# EDMA_TPTC_52A60000h register map
Vendor: Texas Instruments
Peripheral module from a debugger description file (folder AM261x).
Registers are 32-bit, read-only, reset 0x0 unless marked. A register's access mark holds for its fields unless they carry their own. Offsets are as the file gives them; lines under a group give offsets from that group; [hi:lo] are bit positions; {n}, {i} and the like mark numbered series; 'fields as' and 'values as' point back to an identical list; <NAME> marks a mode.

## TPTC
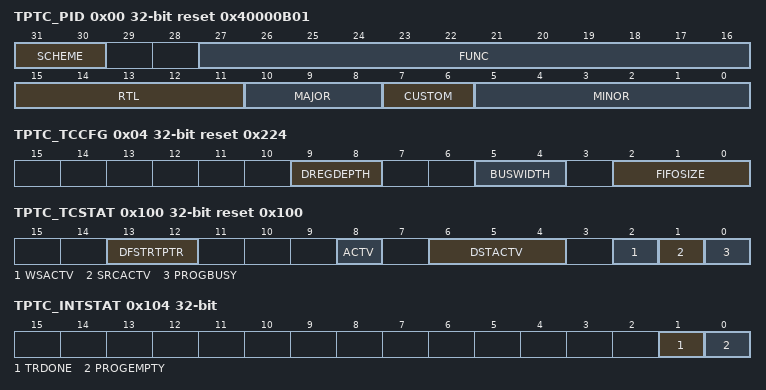
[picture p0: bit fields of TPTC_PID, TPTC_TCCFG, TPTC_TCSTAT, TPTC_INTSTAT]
0x00 TPTC_PID reset 0x40000B01 — Peripheral ID Register.
  [31:30] SCHEME — PID Scheme: Used to distinguish between old ID scheme and current. Spare bit to encode future schemes EDMA uses 'new scheme' indicated with value of 0x1.
  [27:16] FUNC — Function indicates a software compatible module family.
  [15:11] RTL — RTL Version
  [10:8] MAJOR — Major Revision
  [7:6] CUSTOM — Custom revision field: Not used on this version of EDMA.
  [5:0] MINOR — Minor Revision
0x04 TPTC_TCCFG reset 0x224 — TC Configuration Register.
  [9:8] DREGDEPTH — Dst Register FIFO Depth Parameterization
  [5:4] BUSWIDTH — Bus Width Parameterization
  [2:0] FIFOSIZE — Fifo Size Parameterization
0x100 TPTC_TCSTAT reset 0x100 — TC Status Register.
  [13:12] DFSTRTPTR — Dst FIFO Start PointerRepresents the offset to the head entry of Dst Register FIFO in units of entries. Legal values = 0x0 to 0x3
  [8] ACTV — Channel ActiveChannel Active is a logical-OR of each of the BUSY/ACTV signals. The ACTV bit must remain high through the life of a TR.ACTV =0 : Channel is idle.ACTV =1 : Channel is busy.
  [6:4] DSTACTV — Destination Active StateSpecifies the number of TRs that are resident in the Dst Register FIFO at a given instant.Legal values are constrained by the DSTREGDEPTH parameter.
  [2] WSACTV — Write Status ActiveWSACTV =0 : Write status is not pending. Write status has been received for all previously issued write commands.WSACTV =1 : Write Status is pending. Write status has not been received for all previously issued write commands.
  [1] SRCACTV — Source Active StateSRCACTV =0 : Source Active set is idle. Any TR written to Prog Set will immediately transition to Source Active set as long as the Dst FIFO Set is not full [DSTFULL == 1].SRCACTV =1 : Source Active set is busy either performing read transfers or waiting to perform read transfers for current Transfer Request.
  [0] PROGBUSY — Program Register Set BusyPROGBUSY =0 : Prog set idle and is available for programming.PROGBUSY =1 : Prog set busy. User should poll for PROGBUSY equal to '0' prior to re-programming the Program Register set.
0x104 TPTC_INTSTAT — Interrupt Status Register.
  [1] TRDONE — TR Done Event Status:TRDONE =0 : Condition not detected.TRDONE =1 : Set when TC has completed a Transfer Request. TRDONE should be set when the write status is returned for the final write of a TR. Cleared when user writes '1' to INTCLR.TRDONE register bit.
  [0] PROGEMPTY — Program Set Empty Event Status:PROGEMPTY =0 : Condition not detected.PROGEMPTY =1 : Set when Program Register set transitions to empty state. Cleared when user writes '1' to INTCLR.PROGEMPTY register bit.
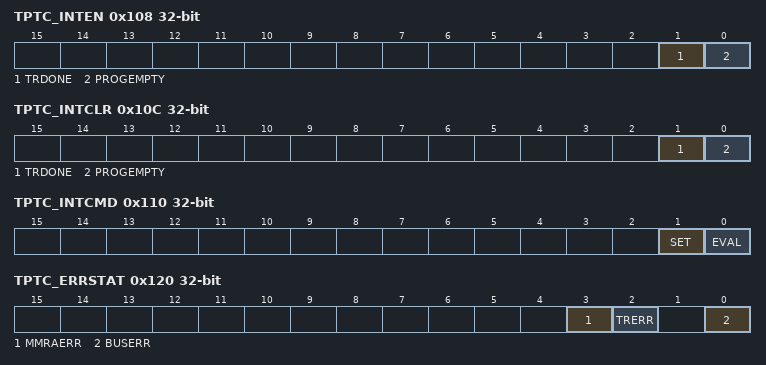
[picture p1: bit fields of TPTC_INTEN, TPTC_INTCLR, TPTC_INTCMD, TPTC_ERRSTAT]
0x108 TPTC_INTEN rw — Interrupt Enable Register.
  [1] TRDONE — TR Done Event Enable:INTEN.TRDONE =0 : TRDONE Event is disabled.INTEN.TRDONE =1 : TRDONE Event is enabled and contributes to interrupt generation
  [0] PROGEMPTY — Program Set Empty Event Enable:INTEN.PROGEMPTY =0 : PROGEMPTY Event is disabled.INTEN.PROGEMPTY =1 : PROGEMPTY Event is enabled and contributes to interrupt generation
0x10C TPTC_INTCLR wo — Interrupt Clear Register.
  [1] TRDONE — TR Done Event Clear:INTCLR.TRDONE =0 : Writes of '0' have no effect.INTCLR.TRDONE =1 : Write of '1' clears INTSTAT.TRDONE bit
  [0] PROGEMPTY — Program Set Empty Event Clear:INTCLR.PROGEMPTY =0 : Writes of '0' have no effect.INTCLR.PROGEMPTY =1 : Write of '1' clears INTSTAT.PROGEMPTY bit
0x110 TPTC_INTCMD wo — Interrupt Command Register.
  [1] SET — Set TPTC interrupt:Write of '1' to SET causes TPTC interrupt to be pulsed unconditionally.Writes of '0' have no affect.
  [0] EVAL — Evaluate state of TPTC interruptWrite of '1' to EVAL causes TPTC interrupt to be pulsed if any of the INTSTAT bits are set to '1'.Writes of '0' have no affect.
0x120 TPTC_ERRSTAT — Error Status Register.
  [3] MMRAERR — MMR Address Error:MMRAERR =0 : Condition not detected.MMRAERR =1 : User attempted to read or write to invalid address configuration memory map. [Is only be set for non-emulation accesses]. No additional error information is recorded.
  [2] TRERR — TR Error:TR detected that violates FIFO Mode transfer [SAM or DAM is '1'] alignment rules or has ACNT or BCNT == 0. No additional error information is recorded.
  [0] BUSERR — Bus Error Event:BUSERR =0:Condition not detected.BUSERR =1:TC has detected an error code on the write response bus or read response bus. Error information is stored in Error Details Register [ERRDET].
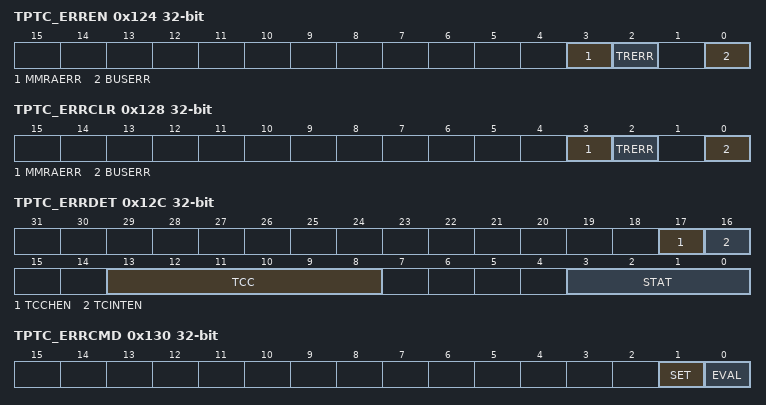
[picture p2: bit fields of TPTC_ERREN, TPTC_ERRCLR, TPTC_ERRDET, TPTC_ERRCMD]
0x124 TPTC_ERREN rw — Error Enable Register.
  [3] MMRAERR — Interrupt enable for ERRSTAT.MMRAERR:ERREN.MMRAERR =0 : BUSERR is disabled.ERREN.MMRAERR =1 : MMRAERR is enabled and contributes to the TPTC error interrupt generation.
  [2] TRERR — Interrupt enable for ERRSTAT.TRERR:ERREN.TRERR =0 : BUSERR is disabled.ERREN.TRERR =1 : TRERR is enabled and contributes to the TPTC error interrupt generation.
  [0] BUSERR — Interrupt enable for ERRSTAT.BUSERR:ERREN.BUSERR =0 : BUSERR is disabled.ERREN.BUSERR =1 : BUSERR is enabled and contributes to the TPTC error interrupt generation.
0x128 TPTC_ERRCLR wo — Error Clear Register.
  [3] MMRAERR — Interrupt clear for ERRSTAT.MMRAERR:ERRCLR.MMRAERR =0 : Writes of '0' have no effect.ERRCLR.MMRAERR =1 : Write of '1' clears ERRSTAT.MMRAERR bit. Write of '1' to ERRCLR.MMRAERR does not clear the ERRDET register.
  [2] TRERR — Interrupt clear for ERRSTAT.TRERR:ERRCLR.TRERR =0 : Writes of '0' have no effect.ERRCLR.TRERR =1 : Write of '1' clears ERRSTAT.TRERR bit. Write of '1' to ERRCLR.TRERR does not clear the ERRDET register.
  [0] BUSERR — Interrupt clear for ERRSTAT.BUSERR:ERRCLR.BUSERR =0 : Writes of '0' have no effect.ERRCLR.BUSERR =1 : Write of '1' clears ERRSTAT.BUSERR bit. Write of '1' to ERRCLR.BUSERR clears the ERRDET register.
0x12C TPTC_ERRDET — Error Details Register.
  [17] TCCHEN — Contains the OPT.TCCHEN value programmed by the user for the Read or Write transaction that resulted in an error.
  [16] TCINTEN — Contains the OPT.TCINTEN value programmed by the user for the Read or Write transaction that resulted in an error.
  [13:8] TCC — Transfer Complete Code: Contains the OPT.TCC value programmed by the user for the Read or Write transaction that resulted in an error.
  [3:0] STAT — Transaction Status:Stores the non-zero status/error code that was detected on the read status or write status bus.MS-bit effectively serves as the read vs. write error code.If read status and write status are returned on the same cycle then the TC chooses non-zero version. If both are non-zero then write status is treated as higher priority.Encoding of errors matches the CBA spec.
0x130 TPTC_ERRCMD wo — Error Command Register.
  [1] SET — Set TPTC error interrupt:Write of '1' to SET causes TPTC error interrupt to be pulsed unconditionally.Writes of '0' have no affect.
  [0] EVAL — Evaluate state of TPTC error interruptWrite of '1' to EVAL causes TPTC error interrupt to be pulsed if any of the ERRSTAT bits are set to '1'.Writes of '0' have no affect.
0x140 TPTC_RDRATE rw — Read Rate Register.
  [2:0] RDRATE — Read Rate Control: Controls the number of cycles between read commands. This is a global setting that applies to all TRs for this TC.
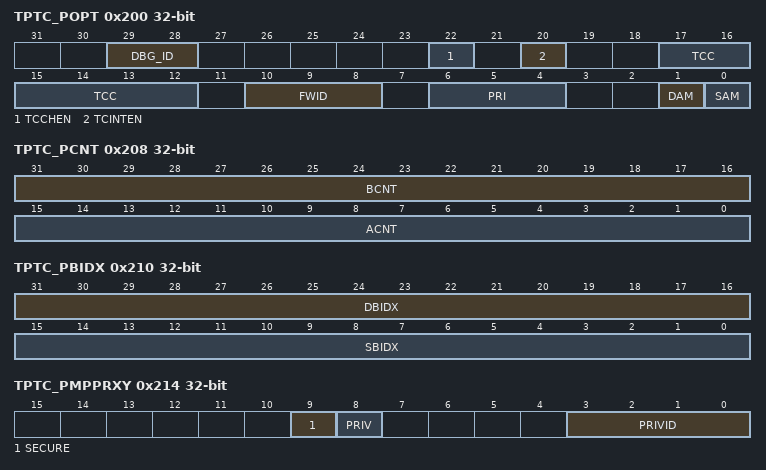
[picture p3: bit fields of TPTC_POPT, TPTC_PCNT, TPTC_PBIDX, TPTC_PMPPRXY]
0x200 TPTC_POPT rw — Prog Set Options.
  [29:28] DBG_ID — Debug IDValue driven on the read [tptc_r_dbg_channel_id] and write [tptc_w_dbg_channel_id] command bus.Used at system level for trace/profiling of user selected transfers in systems that include this feature.
  [22] TCCHEN — Transfer complete chaining enable:0:Transfer complete chaining is disabled.1:Transfer complete chaining is enabled.
  [20] TCINTEN — Transfer complete interrupt enable:0:Transfer complete interrupt is disabled.1:Transfer complete interrupt is enabled.
  [17:12] TCC — Transfer Complete Code: The 6-bit code is used to set the relevant bit in CER or IPR of the TPCC module.
  [10:8] FWID — FIFO width control: Applies if either SAM or DAM is set to FIFO mode.
  [6:4] PRI — Transfer Priority:0:Priority 0 - Highest priority1:Priority 1 ...7:Priority 7 - Lowest priority
  [1] DAM — Destination Address Mode within an array:0:INCR Dst addressing within an array increments.1:FIFO Dst addressing within an array wraps around upon reaching FIFO width.
  [0] SAM — Source Address Mode within an array:0:INCR Src addressing within an array increments.1:FIFO Src addressing within an array wraps around upon reaching FIFO width.
0x204 TPTC_PSRC rw — Prog Set Src Address.
  [31:0] SADDR — Source address for Program Register Set
0x208 TPTC_PCNT rw — Prog Set Count.
  [31:16] BCNT — B-Dimension count. Number of arrays to be transferred where each array is ACNT in length.
  [15:0] ACNT — A-Dimension count. Number of bytes to be transferred in first dimension.
0x20C TPTC_PDST rw — Prog Set Dst Address.
  [31:0] DADDR — Destination address for Program Register Set
0x210 TPTC_PBIDX rw — Prog Set B-Dim Idx.
  [31:16] DBIDX — Dest B-Idx for Program Register Set:B-Idx offset between Destination arrays: Represents the offset in bytes between the starting address of each destination array [recall that there are BCNT arrays of ACNT elements]. DBIDX is always used regardless of whether DAM is Increment or FIFO mode.
  [15:0] SBIDX — Source B-Idx for Program Register Set:B-Idx offset between Source arrays: Represents the offset in bytes between the starting address of each source array [recall that there are BCNT arrays of ACNT elements]. SBIDX is always used regardless of whether SAM is Increment or FIFO mode.
0x214 TPTC_PMPPRXY — Prog Set Mem Protect Proxy.
  [9] SECURE — Secure Level: Deprecated, always read as 0.
  [8] PRIV — Privilege Level:PRIV =0 : User level privilegePRIV =1 : Supervisor level privilegePMPPRXY.PRIV is always updated with the value from the configuration bus privilege field on any/every write to Program Set BIDX Register [trigger register].The PRIV value for the SA Set and DF Set are copied from the value in the Program set along with the remainder of the parameter values.The privilege ID is issued on the VBusM read and write command bus such that the target endpoints can perform memory protection checks based on the PRIV of the external host that sets up the DMA transaction.
  [3:0] PRIVID — Privilege ID:PMPPRXY.PRIVID is always updated with the value from configuration bus privilege ID field on any/every write to Program Set BIDX Register [trigger register].The PRIVID value for the SA Set and DF Set are copied from the value in the Program set along with the remainder of the parameter values.The privilege ID is issued on the VBusM read and write command bus such that the target endpoints can perform memory protection checks based on the privid of the external host that sets up the DMA transaction.
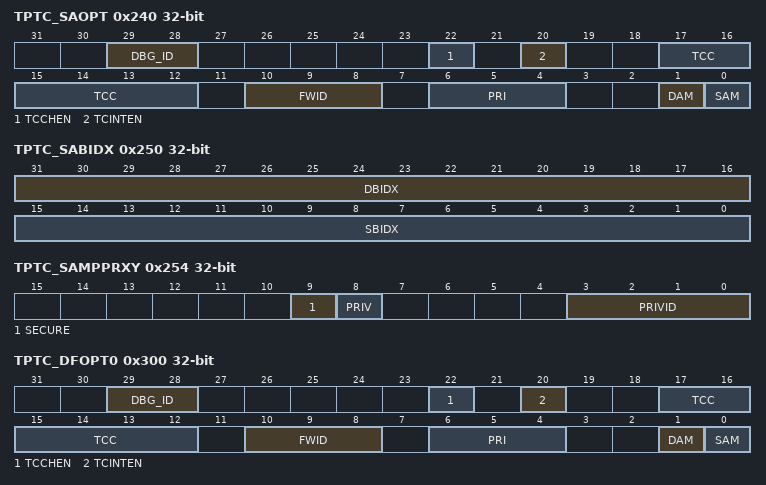
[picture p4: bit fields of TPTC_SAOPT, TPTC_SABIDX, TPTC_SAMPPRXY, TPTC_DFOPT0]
0x240 TPTC_SAOPT — Src Actv Set Options.
  fields as TPTC_POPT
0x244 TPTC_SASRC — Src Actv Set Src Address.
  [31:0] SADDR — Source address for Source Active Register Set
0x248 TPTC_SACNT — Src Actv Set A-Count.
  [22:0] ACNT — A-Dimension count. Number of bytes to be transferred in first dimension.
0x24C TPTC_SADST — Src Actv Set Dst Address.
  [31:0] DADDR — Destination address for Source Active Register Set
0x250 TPTC_SABIDX — Src Actv Set B-Dim Idx.
  [31:16] DBIDX — Dest B-Idx for Source Active Register Set:B-Idx offset between Destination arrays: Represents the offset in bytes between the starting address of each destination array [recall that there are BCNT arrays of ACNT elements]. DBIDX is always used regardless of whether DAM is Increment or FIFO mode.
  [15:0] SBIDX — Source B-Idx for Source Active Register Set:B-Idx offset between Source arrays: Represents the offset in bytes between the starting address of each source array [recall that there are BCNT arrays of ACNT elements]. SBIDX is always used regardless of whether SAM is Increment or FIFO mode.
0x254 TPTC_SAMPPRXY — Src Actv Set Mem Protect Proxy.
  fields as TPTC_PMPPRXY
0x258 TPTC_SACNTRLD — Src Actv Set Cnt Reload.
  [15:0] ACNTRLD — A-Cnt Reload value for Source Active Register set. Value copied from PCNT.ACNT: Represents the originally programmed value of ACNT.The Reload value is used to reinitialize ACNT after each array is serviced [i.e. ACNT decrements to 0]. by the Src offset in bytes between the starting address of each source array [recall that there are BCNT arrays of ACNT bytes]
0x25C TPTC_SASRCBREF — Src Actv Set Src Addr B-Reference.
  [31:0] SADDRBREF — Source address reference for Source Active Register Set:Represents the starting address for the array currently being read. The next array's starting address is calculated as the 'reference address' plus the 'source b-idx' value.
0x260 TPTC_SADSTBREF — Src Actv Set Dst Addr B-Reference.
  [31:0] DADDRBREF — Dst address reference is not applicable for Src Active Register Set. Reads return 0x0.
0x264 TPTC_SABCNT — Src Actv Set B-Count.
  [15:0] BCNT — B-Dimension count:Number of arrays to be transferred where each array is ACNT in length.Count Remaining for Src Active Register Set. Represents the amount of data remaining to be read. Initial value is copied from PCNT. TC decrements ACNT and BCNT as necessary after each read command is issued. Final value should be 0 when TR is complete.
0x280 TPTC_DFCNTRLD — Dst FIFO Set Cnt Reload.
  [15:0] ACNTRLD — A-Cnt Reload value for Destination FIFO Register set. Value copied from PCNT.ACNT: Represents the originally programmed value of ACNT.The Reload value is used to reinitialize ACNT after each array is serviced [i.e. ACNT decrements to 0]. by the Src offset in bytes between the starting address of each source array [recall that there are BCNT arrays of ACNT bytes]
0x284 TPTC_DFSRCBREF — Dst FIFO Set Src Addr B-Reference.
  [31:0] SADDRBREF — Source address reference for Destination FIFO Register Set:Represents the starting address for the array currently being read. The next array's starting address is calculated as the 'reference address' plus the 'source b-idx' value.
0x300 TPTC_DFOPT0 — Dst FIFO Set Options.
  fields as TPTC_POPT
0x304 TPTC_DFSRC0 — Dst FIFO Set Src Address.
  [31:0] SADDR — Source address is not applicable for Dst FIFO Register Set: Reads return 0x0.
0x308 TPTC_DFACNT0 — Dst FIFO Set A-Count.
  [22:0] ACNT — A-Dimension count. Number of bytes to be transferred infirst dimension.
0x30C TPTC_DFDST0 — Dst FIFO Set Dst Address.
  [31:0] DADDR — Destination address for Dst FIFO Register Set:Initial value is copied from PDST.DADDR.TC updates value according to destination addressing mode [OPT.SAM] and/or dest index value [BIDX.DBIDX] after each write command is issued.When a TR is complete the final value should be the address of the last write command issued.
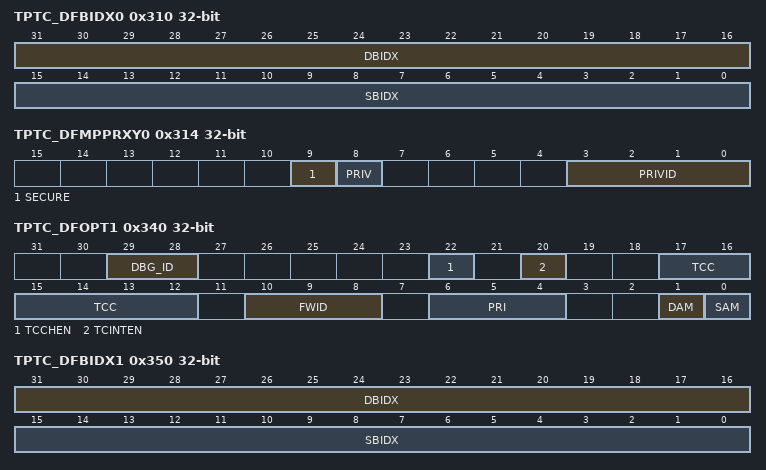
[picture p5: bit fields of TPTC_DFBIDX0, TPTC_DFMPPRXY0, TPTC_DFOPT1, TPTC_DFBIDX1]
0x310 TPTC_DFBIDX0 — Dst FIFO Set B-Dim Idx.
  [31:16] DBIDX — Dest B-Idx for Dest FIFO Register Set.Value copied from PBIDX: B-Idx offset between Destination arrays: Represents the offset in bytes between the starting address of each destination array [recall that there are BCNT arrays of ACNT elements].DBIDX is always used regardless of whether DAM is Increment or FIFO mode.
  [15:0] SBIDX — Src B-Idx for Dest FIFO Register Set.Value copied from PBIDX: B-Idx offset between Source arrays: Represents the offset in bytes between the starting address of each source array [recall that there are BCNT arrays of ACNT elements].SBIDX is always used regardless of whether SAM is Increment or FIFO mode.
0x314 TPTC_DFMPPRXY0 — Dst FIFO Set Mem Protect Proxy.
  fields as TPTC_PMPPRXY
0x318 TPTC_DFBCNT0 — Dst FIFO Set B-Count.
  [15:0] BCNT — B-Count Remaining for Dst Register Set:Number of arrays to be transferred where each array is ACNT in length.Represents the amount of data remaining to be written.Initial value is copied from PCNT.TC decrements ACNT and BCNT as necessary after each write dataphase is issued. Final value should be 0 when TR is complete.
0x340 TPTC_DFOPT1 — Dst FIFO Set Options.
  fields as TPTC_POPT
0x344 TPTC_DFSRC1 — Dst FIFO Set Src Address.
  fields as TPTC_DFSRC0
0x348 TPTC_DFACNT1 — Dst FIFO Set A-Count.
  fields as TPTC_DFACNT0
0x34C TPTC_DFDST1 — Dst FIFO Set Dst Address.
  fields as TPTC_DFDST0
0x350 TPTC_DFBIDX1 — Dst FIFO Set B-Dim Idx.
  fields as TPTC_DFBIDX0
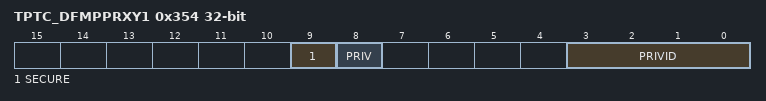
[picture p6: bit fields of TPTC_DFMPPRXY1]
0x354 TPTC_DFMPPRXY1 — Dst FIFO Set Mem Protect Proxy.
  fields as TPTC_PMPPRXY
0x358 TPTC_DFBCNT1 — Dst FIFO Set B-Count.
  fields as TPTC_DFBCNT0
